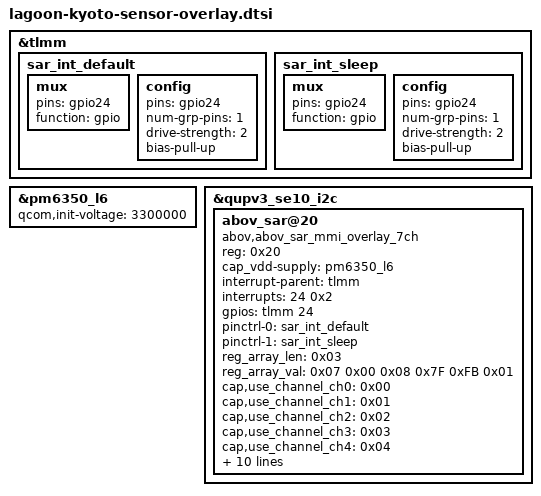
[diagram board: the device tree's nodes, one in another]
/* Copyright (c) 2019, The Linux Foundation. All rights reserved.
 *
 * This program is free software; you can redistribute it and/or modify
 * it under the terms of the GNU General Public License version 2 and
 * only version 2 as published by the Free Software Foundation.
 *
 * This program is distributed in the hope that it will be useful,
 * but WITHOUT ANY WARRANTY; without even the implied warranty of
 * MERCHANTABILITY or FITNESS FOR A PARTICULAR PURPOSE.  See the
 * GNU General Public License for more details.
 */

&tlmm {
	sar_int_default: sar_int_default {
			mux {
				pins = "gpio24";
				function =  "gpio";
			};
			config {
				pins = "gpio24";
				num-grp-pins = <1>;
				drive-strength = <2>;
				bias-pull-up;
			};
	};

	sar_int_sleep: sar_int_sleep {
			mux {
				pins = "gpio24";
				function =  "gpio";
			};
			config {
				pins = "gpio24";
				num-grp-pins = <1>;
				drive-strength = <2>;
				bias-pull-up;
			};
	};
};

&pm6350_l6 {
        qcom,init-voltage = <3300000>;
        status = "ok";
};

&qupv3_se10_i2c {
	status = "ok";
	abov_sar@20 {
		status = "ok";
        	compatible = "abov,abov_sar_mmi_overlay_7ch";
        	reg = <0x20>;
        	cap_vdd-supply = <&pm6350_l6>;
        	interrupt-parent = <&tlmm>;
        	interrupts = <24 0x2>;
        	gpios = <&tlmm 24 0x2>;
        	pinctrl-names = "default","sleep";
		pinctrl-0 = <&sar_int_default>;
		pinctrl-1 = <&sar_int_sleep>;
        	reg_array_len = <0x03>;
        	reg_array_val = <0x07 0x00 0x08 0x7F 0xFB 0x01>;
		cap,use_channel_ch0 = <0x00>;
		cap,use_channel_ch1 = <0x01>;
        	cap,use_channel_ch2 = <0x02>;
		cap,use_channel_ch3 = <0x03>;
		cap,use_channel_ch4 = <0x04>;
		ch0_name = "capsense_bottom_right";
		ch1_name = "capsense_bottom_left";
        	ch2_name = "capsense_top_left";
		ch3_name = "capsense_top_mid";
		ch4_name = "capsense_top_right";
        	label = "AbovCapSense";
        	cap,channel_number = <0x05>;
		/**
		*A96T346DF/A96T349DF FW MODE:0x39
		* A96T346HW/A96T349HW FW MODE:0x3A
		* A96T376EF FW MODE:0x70
		* A96T375DF FW MODE:0x71
		**/
		cap,fw_mode_ret = <0x70>;
		/**
		* 2CH:0x05
		* 3CH:0x15
		* 4CH:0x55
		* 5CH:0x155
		**/
		button_mask = <0x155>;
		/**
		*A96T346DF/A96T349DF/A96T346HW/A96T349HW: 1400
		* A96T376EF/A96T375DF:3000
		**/
		cap,flash_erase_time = <3000>;
	};
};
